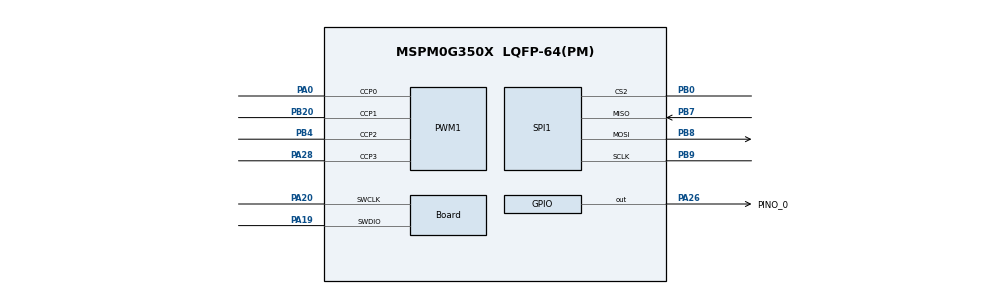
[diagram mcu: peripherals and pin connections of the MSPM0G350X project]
//@cliArgs --device "MSPM0G350X" --package "LQFP-64(PM)" --part "Default"
// @cliArgs --board /ti/boards/LP_MSPM0G3507 --rtos nortos

/**
 * Import the modules used in this configuration.
 */
const ProjectConfig = scripting.addModule("/ti/project_config/ProjectConfig");
const ADC12       = scripting.addModule("/ti/driverlib/ADC12", {}, false);
const ADC121      = ADC12.addInstance();
const ADC122      = ADC12.addInstance();
const Board       = scripting.addModule("/ti/driverlib/Board");
const CAPTURE     = scripting.addModule("/ti/driverlib/CAPTURE", {}, false);
const CAPTURE1    = CAPTURE.addInstance();
const COMP        = scripting.addModule("/ti/driverlib/COMP", {}, false);
const COMP1       = COMP.addInstance();
const COMP2       = COMP.addInstance();
const COMP3       = COMP.addInstance();
const CRC         = scripting.addModule("/ti/driverlib/CRC");
const GPIO        = scripting.addModule("/ti/driverlib/GPIO", {}, false);
const GPIO1       = GPIO.addInstance();
const MATHACL     = scripting.addModule("/ti/driverlib/MATHACL");
const PWM         = scripting.addModule("/ti/driverlib/PWM", {}, false);
const PWM1        = PWM.addInstance();
const SPI         = scripting.addModule("/ti/driverlib/SPI", {}, false);
const SPI1        = SPI.addInstance();
const SYSCTL      = scripting.addModule("/ti/driverlib/SYSCTL");
const TIMER       = scripting.addModule("/ti/driverlib/TIMER", {}, false);
const TIMER1      = TIMER.addInstance();
const TIMERFault  = scripting.addModule("/ti/driverlib/TIMERFault", {}, false);
const TIMERFault1 = TIMERFault.addInstance();

/**
 * Write custom configuration values to the imported modules.
 */
ProjectConfig.genDisable = true;

const divider6       = system.clockTree["PLL_CLK2X_DIV"];
divider6.divideValue = 4;

const divider9       = system.clockTree["UDIV"];
divider9.divideValue = 2;

const multiplier2         = system.clockTree["PLL_QDIV"];
multiplier2.multiplyValue = 5;

const mux8       = system.clockTree["HSCLKMUX"];
mux8.inputSelect = "HSCLKMUX_SYSPLL2X";

ADC121.samplingOperationMode             = "sequence";
ADC121.trigSrc                           = "DL_ADC12_TRIG_SRC_EVENT";
ADC121.sampleTime1                       = "1us";
ADC121.adcMem2chansel                    = "DL_ADC12_INPUT_CHAN_2";
ADC121.adcMem3chansel                    = "DL_ADC12_INPUT_CHAN_5";
ADC121.repeatMode                        = true;
ADC121.endAdd                            = 1;
ADC121.adcMem1chansel                    = "DL_ADC12_INPUT_CHAN_2";
ADC121.powerDownMode                     = "DL_ADC12_POWER_DOWN_MODE_MANUAL";
ADC121.adcMem0chansel                    = "DL_ADC12_INPUT_CHAN_3";
ADC121.enabledInterrupts                 = ["DL_ADC12_INTERRUPT_MEM1_RESULT_LOADED"];
ADC121.$name                             = "GENERIC_ADC_0";
ADC121.adcClk_Freq_cconrun               = true;
ADC121.adcMem1trig                       = "DL_ADC12_TRIGGER_MODE_TRIGGER_NEXT";
ADC121.subChanID                         = 12;
ADC121.hwNumerator                       = "DL_ADC12_HW_AVG_NUM_ACC_8";
ADC121.hwDenominator                     = "DL_ADC12_HW_AVG_DEN_DIV_BY_8";
ADC121.sampClkSrc                        = "DL_ADC12_CLOCK_ULPCLK";
ADC121.sampleTime0                       = "100ns";
ADC121.peripheral.$assign                = "ADC0";
ADC121.peripheral.adcPin2.$assign        = "PA25";
ADC121.peripheral.adcPin3.$assign        = "PA24";
ADC121.adcPin2Config.hideOutputInversion = scripting.forceWrite(false);
ADC121.adcPin3Config.hideOutputInversion = scripting.forceWrite(false);

ADC122.samplingOperationMode             = "sequence";
ADC122.trigSrc                           = "DL_ADC12_TRIG_SRC_EVENT";
ADC122.adcMem2chansel                    = "DL_ADC12_INPUT_CHAN_2";
ADC122.sampleTime1                       = "1us";
ADC122.adcMem0chansel                    = "DL_ADC12_INPUT_CHAN_2";
ADC122.powerDownMode                     = "DL_ADC12_POWER_DOWN_MODE_MANUAL";
ADC122.$name                             = "GENERIC_ADC_1";
ADC122.adcClk_Freq_cconrun               = true;
ADC122.subChanID                         = 12;
ADC122.sampClkSrc                        = "DL_ADC12_CLOCK_ULPCLK";
ADC122.sampleTime0                       = "100ns";
ADC122.endAdd                            = 1;
ADC122.adcMem1trig                       = "DL_ADC12_TRIGGER_MODE_TRIGGER_NEXT";
ADC122.adcMem1chansel                    = "DL_ADC12_INPUT_CHAN_3";
ADC122.enabledInterrupts                 = ["DL_ADC12_INTERRUPT_MEM1_RESULT_LOADED"];
ADC122.configWinCompLowThld              = 2046;
ADC122.configWinCompHighThld             = 2200;
ADC122.repeatMode                        = true;
ADC122.peripheral.$assign                = "ADC1";
ADC122.peripheral.adcPin2.$assign        = "PA17";
ADC122.peripheral.adcPin3.$assign        = "PA18";
ADC122.adcPin2Config.hideOutputInversion = scripting.forceWrite(false);

Board.peripheral.$assign          = "DEBUGSS";
Board.peripheral.swclkPin.$assign = "PA20";
Board.peripheral.swdioPin.$assign = "PA19";

CAPTURE1.timerStartTimer      = true;
CAPTURE1.captSelect           = "Trigger";
CAPTURE1.subscriberPort       = "FSUB0";
CAPTURE1.interrupts           = ["CC0_DN"];
CAPTURE1.multi_ch0_input_mode = "DL_TIMER_CC_IN_SEL_FSUB0";
CAPTURE1.multi_ch_zero        = 0;
CAPTURE1.$name                = "GENERIC_CAPTURE_0";
CAPTURE1.ccIndexMulti         = [0];
CAPTURE1.subscriberChannel    = 1;
CAPTURE1.timerPeriod          = "800us";
CAPTURE1.peripheral.$assign   = "TIMA1";

COMP1.vSource                               = "DL_COMP_REF_SOURCE_VDDA_DAC";
COMP1.enabledEvents                         = ["DL_COMP_EVENT_OUTPUT_EDGE"];
COMP1.terminalSelect                        = "DL_COMP_REF_TERMINAL_SELECT_NEG";
COMP1.posChannel                            = "DL_COMP_IPSEL_CHANNEL_2";
COMP1.negChannel                            = "DL_COMP_IMSEL_CHANNEL_1";
COMP1.channelEnable                         = ["POS"];
COMP1.controlSelect                         = "DL_COMP_DAC_CONTROL_SW";
COMP1.outputEnable                          = true;
COMP1.pubChanID                             = 1;
COMP1.$name                                 = "GENERIC_COMP_0";
COMP1.hysteresis                            = "DL_COMP_HYSTERESIS_30";
COMP1.enableOutputFilter                    = true;
COMP1.selectOutputFilter                    = "DL_COMP_FILTER_DELAY_500";
COMP1.outputInterruptEdge                   = "DL_COMP_OUTPUT_INT_EDGE_FALLING";
COMP1.peripheral.$assign                    = "COMP0";
COMP1.peripheral.compPinPos2.$assign        = "PA14";
COMP1.peripheral.compPinOut.$assign         = "PA11";

COMP2.channelEnable                         = ["POS"];
COMP2.vSource                               = "DL_COMP_REF_SOURCE_VDDA_DAC";
COMP2.terminalSelect                        = "DL_COMP_REF_TERMINAL_SELECT_NEG";
COMP2.controlSelect                         = "DL_COMP_DAC_CONTROL_SW";
COMP2.pubChanID                             = 2;
COMP2.enabledEvents                         = ["DL_COMP_EVENT_OUTPUT_EDGE"];
COMP2.outputEnable                          = true;
COMP2.$name                                 = "GENERIC_COMP_1";
COMP2.enableOutputFilter                    = true;
COMP2.selectOutputFilter                    = "DL_COMP_FILTER_DELAY_500";
COMP2.hysteresis                            = "DL_COMP_HYSTERESIS_30";
COMP2.outputInterruptEdge                   = "DL_COMP_OUTPUT_INT_EDGE_FALLING";
COMP2.peripheral.$assign                    = "COMP1";
COMP2.peripheral.compPinPos0.$assign        = "PB26";
COMP2.peripheral.compPinOut.$assign         = "PA3";

COMP3.channelEnable                         = ["POS"];
COMP3.vSource                               = "DL_COMP_REF_SOURCE_VDDA_DAC";
COMP3.terminalSelect                        = "DL_COMP_REF_TERMINAL_SELECT_NEG";
COMP3.controlSelect                         = "DL_COMP_DAC_CONTROL_SW";
COMP3.pubChanID                             = 3;
COMP3.enabledEvents                         = ["DL_COMP_EVENT_OUTPUT_EDGE"];
COMP3.$name                                 = "GENERIC_COMP_2";
COMP3.outputEnable                          = true;
COMP3.enableOutputFilter                    = true;
COMP3.selectOutputFilter                    = "DL_COMP_FILTER_DELAY_500";
COMP3.hysteresis                            = "DL_COMP_HYSTERESIS_30";
COMP3.outputInterruptEdge                   = "DL_COMP_OUTPUT_INT_EDGE_FALLING";
COMP3.peripheral.$assign                    = "COMP2";
COMP3.peripheral.compPinPos0.$assign        = "PB21";
COMP3.peripheral.compPinOut.$assign         = "PB27";

GPIO1.$name                         = "GENERIC_GPIO_OUT";
GPIO1.associatedPins[0].$name       = "PINO_0";
GPIO1.associatedPins[0].pin.$assign = "PA26";

PWM1.pwmMode                            = "CENTER_ALIGN";
PWM1.deadBandEn                         = true;
PWM1.dbRiseDelayTimerCount              = 32;
PWM1.dbFallDelayTimerCount              = 32;
PWM1.dbInsertionMode                    = "Mode1";
PWM1.$name                              = "GENERIC_PWM_0";
PWM1.ccIndexCmpl                        = [1,2,3];
PWM1.enableShadowLoad                   = true;
PWM1.timerStartTimer                    = true;
PWM1.faultHandlerEn                     = true;
PWM1.faultSource                        = ["2"];
PWM1.faultConditionDuration             = "FL_LATCH_SW_CLR";
PWM1.faultInput                         = "FI_DEPENDENT";
PWM1.faultInputEn                       = "FIEN_ENABLED";
PWM1.faultTimerCountEntry               = "FAULT_ENTRY_CTR_SUSP_COUNT";
PWM1.faultInputFilterEn                 = true;
PWM1.faultChannel1BehaviorEntry         = "LOW";
PWM1.faultChannel1BehaviorExit          = "LOW";
PWM1.faultChannel2BehaviorEntry         = "LOW";
PWM1.faultChannel2BehaviorExit          = "LOW";
PWM1.faultChannel3BehaviorEntry         = "LOW";
PWM1.faultChannel3BehaviorExit          = "LOW";
PWM1.faultInputDetect                   = true;
PWM1.faultFilterSamplePeriod            = "8";
PWM1.event2ControllerInterruptEn        = ["ZERO_EVENT"];
PWM1.event1PublisherChannel             = 12;
PWM1.ccIndex                            = [0,1,2,3];
PWM1.event1ControllerInterruptEn        = ["CC0_DN_EVENT"];
PWM1.timerCount                         = 8000;
PWM1.enableRepeatCounter                = true;
PWM1.interrupts                         = ["CC0_UP_EVENT"];
PWM1.peripheral.$assign                 = "TIMA0";
PWM1.peripheral.ccp0Pin.$assign         = "PA0";
PWM1.peripheral.ccp1Pin.$assign         = "PB20";
PWM1.peripheral.ccp1Pin_cmpl.$assign    = "PB13";
PWM1.peripheral.ccp2Pin.$assign         = "PB4";
PWM1.peripheral.ccp2Pin_cmpl.$assign    = "PB1";
PWM1.peripheral.ccp3Pin.$assign         = "PA28";
PWM1.peripheral.ccp3Pin_cmpl.$assign    = "PA31";
PWM1.PWM_CHANNEL_0.$name                = "ti_driverlib_pwm_PWMTimerCC1";
PWM1.PWM_CHANNEL_1.$name                = "ti_driverlib_pwm_PWMTimerCC2";
PWM1.PWM_CHANNEL_1.shadowUpdateMode     = "ZERO_EVT";
PWM1.ccp0PinConfig.direction            = scripting.forceWrite("OUTPUT");
PWM1.ccp0PinConfig.hideOutputInversion  = scripting.forceWrite(false);
PWM1.ccp0PinConfig.onlyInternalResistor = scripting.forceWrite(false);
PWM1.ccp0PinConfig.passedPeripheralType = scripting.forceWrite("Digital");
PWM1.ccp1PinConfig.direction            = scripting.forceWrite("OUTPUT");
PWM1.ccp1PinConfig.hideOutputInversion  = scripting.forceWrite(false);
PWM1.ccp1PinConfig.onlyInternalResistor = scripting.forceWrite(false);
PWM1.ccp1PinConfig.passedPeripheralType = scripting.forceWrite("Digital");
PWM1.PWM_CHANNEL_2.$name                = "ti_driverlib_pwm_PWMTimerCC6";
PWM1.PWM_CHANNEL_2.shadowUpdateMode     = "ZERO_EVT";
PWM1.PWM_CHANNEL_3.$name                = "ti_driverlib_pwm_PWMTimerCC0";
PWM1.PWM_CHANNEL_3.shadowUpdateMode     = "ZERO_EVT";

SPI1.txFifoThreshold                    = "DL_SPI_TX_FIFO_LEVEL_EMPTY";
SPI1.targetBitRate                      = 1000000;
SPI1.dataSize                           = 16;
SPI1.rxFifoThreshold                    = "DL_SPI_RX_FIFO_LEVEL_FULL";
SPI1.phase                              = "1";
SPI1.chipSelect                         = ["2"];
SPI1.spiClkDiv                          = "8";
SPI1.$name                              = "GENERIC_SPI_0";
SPI1.peripheral.$assign                 = "SPI1";
SPI1.peripheral.sclkPin.$assign         = "PB9";
SPI1.peripheral.mosiPin.$assign         = "PB8";
SPI1.peripheral.misoPin.$assign         = "PB7";
SPI1.peripheral.cs2Pin.$assign          = "PB0";
SPI1.sclkPinConfig.direction            = scripting.forceWrite("OUTPUT");
SPI1.sclkPinConfig.onlyInternalResistor = scripting.forceWrite(false);
SPI1.sclkPinConfig.passedPeripheralType = scripting.forceWrite("Digital");
SPI1.mosiPinConfig.direction            = scripting.forceWrite("OUTPUT");
SPI1.mosiPinConfig.hideOutputInversion  = scripting.forceWrite(false);
SPI1.mosiPinConfig.onlyInternalResistor = scripting.forceWrite(false);
SPI1.mosiPinConfig.passedPeripheralType = scripting.forceWrite("Digital");
SPI1.misoPinConfig.onlyInternalResistor = scripting.forceWrite(false);
SPI1.misoPinConfig.passedPeripheralType = scripting.forceWrite("Digital");
SPI1.cs2PinConfig.direction             = scripting.forceWrite("OUTPUT");
SPI1.cs2PinConfig.hideOutputInversion   = scripting.forceWrite(false);
SPI1.cs2PinConfig.onlyInternalResistor  = scripting.forceWrite(false);
SPI1.cs2PinConfig.passedPeripheralType  = scripting.forceWrite("Digital");

SYSCTL.SYSPLL_CLK2XEn     = true;
SYSCTL.SYSPLL_Pdiv        = 1;
SYSCTL.SYSPLL_Qdiv        = 5;
SYSCTL.SYSPLL_CLK2XDiv    = 3;
SYSCTL.MCLKSource         = "HSCLK";
SYSCTL.HSCLKSource        = "SYSPLLCLK2X";
SYSCTL.validateClkStatus  = true;
SYSCTL.MFPCLKEn           = true;
SYSCTL.UDIV               = "2";
SYSCTL.peripheral.$assign = "SYSCTL";

TIMER1.timerMode          = "PERIODIC";
TIMER1.timerPeriod        = "1 ms";
TIMER1.timerClkDiv        = 2;
TIMER1.timerStartTimer    = true;
TIMER1.interrupts         = ["ZERO"];
TIMER1.$name              = "GENERIC_TIM_0";
TIMER1.peripheral.$assign = "TIMG0";

PWM1.associatedFault                             = TIMERFault1;
TIMERFault1.enabledFaults                        = ["2"];
TIMERFault1.$name                                = "GENERIC_TIM_FAULT_0";
TIMERFault1.faultPin2.$assign                    = "PA27";
TIMERFault1.faultPin2Config.direction            = scripting.forceWrite("OUTPUT");
TIMERFault1.faultPin2Config.hideOutputInversion  = scripting.forceWrite(false);
TIMERFault1.faultPin2Config.passedPeripheralType = scripting.forceWrite("Digital");
